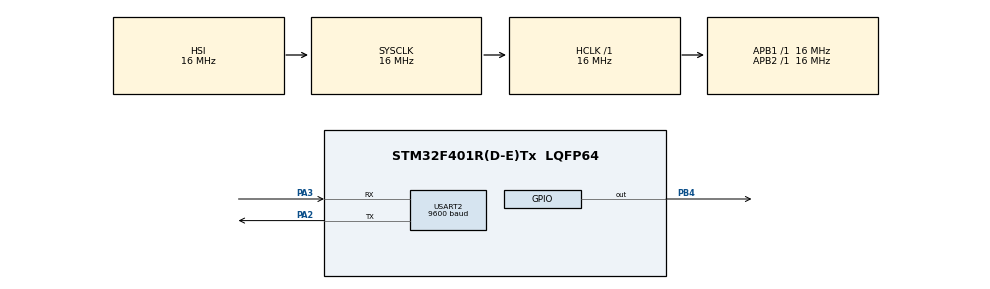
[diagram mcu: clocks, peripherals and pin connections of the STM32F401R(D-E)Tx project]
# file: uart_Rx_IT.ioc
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Mcu.Family=STM32F4
Mcu.Name=STM32F401R(D-E)Tx
Mcu.Package=LQFP64
NVIC.PriorityGroup=NVIC_PRIORITYGROUP_4
NVIC.USART2_IRQn=true\:0\:0\:false\:false\:true\:true
PA2.Mode=Asynchronous
PA2.Signal=USART2_TX
PA3.Mode=Asynchronous
PA3.Signal=USART2_RX
PB4.Signal=GPIO_Output
ProjectManager.HeapSize=0x200
ProjectManager.StackSize=0x400
ProjectManager.TargetToolchain=SW4STM32
RCC.AHBFreq_Value=16000000
RCC.APB1Freq_Value=16000000
RCC.APB1TimFreq_Value=16000000
RCC.APB2Freq_Value=16000000
RCC.APB2TimFreq_Value=16000000
RCC.CortexFreq_Value=16000000
RCC.HCLKFreq_Value=16000000
RCC.HSE_VALUE=25000000
RCC.HSI_VALUE=16000000
RCC.LSE_VALUE=32768
RCC.SYSCLKFreq_VALUE=16000000
RCC.VCOOutputFreq_Value=192000000
USART2.BaudRate=9600
USART2.VirtualMode=VM_ASYNC
board=uart_Rx_IT

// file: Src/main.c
/**
  ******************************************************************************
  * File Name          : main.c
  * Description        : Main program body
  ******************************************************************************
  ** This notice applies to any and all portions of this file
  * that are not between comment pairs USER CODE BEGIN and
  * USER CODE END. Other portions of this file, whether
  * inserted by the user or by software development tools
  * are owned by their respective copyright owners.
  *
  * COPYRIGHT(c) 2018 STMicroelectronics
  *
  * Redistribution and use in source and binary forms, with or without modification,
  * are permitted provided that the following conditions are met:
  *   1. Redistributions of source code must retain the above copyright notice,
  *      this list of conditions and the following disclaimer.
  *   2. Redistributions in binary form must reproduce the above copyright notice,
  *      this list of conditions and the following disclaimer in the documentation
  *      and/or other materials provided with the distribution.
  *   3. Neither the name of STMicroelectronics nor the names of its contributors
  *      may be used to endorse or promote products derived from this software
  *      without specific prior written permission.
  *
  * THIS SOFTWARE IS PROVIDED BY THE COPYRIGHT HOLDERS AND CONTRIBUTORS "AS IS"
  * AND ANY EXPRESS OR IMPLIED WARRANTIES, INCLUDING, BUT NOT LIMITED TO, THE
  * IMPLIED WARRANTIES OF MERCHANTABILITY AND FITNESS FOR A PARTICULAR PURPOSE ARE
  * DISCLAIMED. IN NO EVENT SHALL THE COPYRIGHT HOLDER OR CONTRIBUTORS BE LIABLE
  * FOR ANY DIRECT, INDIRECT, INCIDENTAL, SPECIAL, EXEMPLARY, OR CONSEQUENTIAL
  * DAMAGES (INCLUDING, BUT NOT LIMITED TO, PROCUREMENT OF SUBSTITUTE GOODS OR
  * SERVICES; LOSS OF USE, DATA, OR PROFITS; OR BUSINESS INTERRUPTION) HOWEVER
  * CAUSED AND ON ANY THEORY OF LIABILITY, WHETHER IN CONTRACT, STRICT LIABILITY,
  * OR TORT (INCLUDING NEGLIGENCE OR OTHERWISE) ARISING IN ANY WAY OUT OF THE USE
  * OF THIS SOFTWARE, EVEN IF ADVISED OF THE POSSIBILITY OF SUCH DAMAGE.
  *
  ******************************************************************************
  */

#include "main.h"
#include "stm32f4xx_hal.h"
#include "usart.h"
#include "gpio.h"
#include <string.h>

/* USER CODE BEGIN PV */
/* Private variables ---------------------------------------------------------*/

uint8_t my_buffer[10],UartRcvIndx,UartRxCplt;
char RxBuffer[1024];
uartIpCmdTypeDef cmd;
extern int printf(const char *msg, ...);
int uartCmdParser(char *);
/* USER CODE END PV */

void SystemClock_Config(void);

/* USER CODE BEGIN PFP */
/* Private function prototypes -----------------------------------------------*/
uint8_t uartCmdStore(uint8_t *, char *);
/* USER CODE END PFP */

int main(void)
{

  /* MCU Configuration----------------------------------------------------------*/

  /* Reset of all peripherals, Initializes the Flash interface and the Systick. */
  HAL_Init();

  /* Configure the system clock */
  SystemClock_Config();

  /* Initialize all configured peripherals */
  MX_GPIO_Init();
  MX_USART2_UART_Init();

  /* USER CODE BEGIN 2 */
  /*Configure UART to receive interrupt */

    printf("\nHello, this program demonstrates UART Receive using interrupt using STM32F401RE\n");
    HAL_UART_Receive_IT(&huart2,(uint8_t *)my_buffer,1);
  /* USER CODE END 2 */

  /* Infinite loop */
  /* USER CODE BEGIN WHILE */

  while (1)
  {
	  if(UartRxCplt)
	    {

	  	  //printf("%.*s\n",UartRcvIndx,RxBuffer);
	  	  UartRxCplt = 0;
	  	  //uartCmdParser(RxBuffer);
	  	  memset(RxBuffer,'0',UartRcvIndx);
	  	  UartRcvIndx=0;
	    }
  /* USER CODE END WHILE */

  }

}

/** System Clock Configuration
*/
void SystemClock_Config(void)
{

  RCC_OscInitTypeDef RCC_OscInitStruct;
  RCC_ClkInitTypeDef RCC_ClkInitStruct;

    /**Configure the main internal regulator output voltage
    */
  __HAL_RCC_PWR_CLK_ENABLE();

  __HAL_PWR_VOLTAGESCALING_CONFIG(PWR_REGULATOR_VOLTAGE_SCALE2);

    /**Initializes the CPU, AHB and APB busses clocks
    */
  RCC_OscInitStruct.OscillatorType = RCC_OSCILLATORTYPE_HSI;
  RCC_OscInitStruct.HSIState = RCC_HSI_ON;
  RCC_OscInitStruct.HSICalibrationValue = 16;
  RCC_OscInitStruct.PLL.PLLState = RCC_PLL_NONE;
  if (HAL_RCC_OscConfig(&RCC_OscInitStruct) != HAL_OK)
  {
    _Error_Handler(__FILE__, __LINE__);
  }

    /**Initializes the CPU, AHB and APB busses clocks
    */
  RCC_ClkInitStruct.ClockType = RCC_CLOCKTYPE_HCLK|RCC_CLOCKTYPE_SYSCLK
                              |RCC_CLOCKTYPE_PCLK1|RCC_CLOCKTYPE_PCLK2;
  RCC_ClkInitStruct.SYSCLKSource = RCC_SYSCLKSOURCE_HSI;
  RCC_ClkInitStruct.AHBCLKDivider = RCC_SYSCLK_DIV1;
  RCC_ClkInitStruct.APB1CLKDivider = RCC_HCLK_DIV1;
  RCC_ClkInitStruct.APB2CLKDivider = RCC_HCLK_DIV1;

  if (HAL_RCC_ClockConfig(&RCC_ClkInitStruct, FLASH_LATENCY_0) != HAL_OK)
  {
    _Error_Handler(__FILE__, __LINE__);
  }

    /**Configure the Systick interrupt time
    */
  HAL_SYSTICK_Config(HAL_RCC_GetHCLKFreq()/1000);

    /**Configure the Systick
    */
  HAL_SYSTICK_CLKSourceConfig(SYSTICK_CLKSOURCE_HCLK);

  /* SysTick_IRQn interrupt configuration */
  HAL_NVIC_SetPriority(SysTick_IRQn, 0, 0);
}

/* USER CODE BEGIN 4 */
void HAL_UART_RxCpltCallback(UART_HandleTypeDef *UartHandle)
{

	//printf("\nReceived callback\n");
	/*store UART Rx data to buffer & return the size of received uart data */
	UartRcvIndx = uartCmdStore(my_buffer,RxBuffer);

	//printf("Received char is %c\n",my_buffer[0]);
	/*enable interrupt again after UART reception complete */
	HAL_UART_Receive_IT(UartHandle,(uint8_t *)my_buffer,1);
	//printf("enabled interrupt again\n");

}
uint8_t uartCmdStore(uint8_t *my_buffer,char *RxBuffer)
{
	/* if i/p not '\n': i) uart rx not complete ii) store i/p data to buffer */
	if(*my_buffer!=13)
	{
		if(UartRxCplt==1)
			UartRxCplt = 0;
		RxBuffer[UartRcvIndx++] = my_buffer[0];
	}

	/* if i/p '\n': set uart rx to cplt */
	/*user has to call in main function to analyze the input data stored in Rxbuffer by checking UartRxCplt variable */
	else
	{
		RxBuffer[UartRcvIndx] = '\0';
		UartRxCplt = 1;
		printf("Received data is:");
		printf("%s\n",RxBuffer);
		memset(RxBuffer,'0',UartRcvIndx);
	}
	return UartRcvIndx;

}
/* not used now, but can be used to interpret the input uart command */
int uartCmdParser(char *RxBuffer)
{
	char *uartIp=RxBuffer,*pch,*tmp;
	/* initialize uartIpCmd structure */
	cmd.ctrl = "set";
	cmd.param = "param";
	cmd.value = 0;

	/* get ctrl section of the i/p uart command */
	sprintf(cmd.ctrl,"%.*s",strtok(uartIp,' ')-RxBuffer,RxBuffer);
	tmp = uartIp;
	/* get param section of i/p uart command */
	sprintf(cmd.param,"%.*s",strtok(uartIp,'=')-tmp,tmp);
	/* get value section of i/p uart command */
	int *intUartIp = atoi(uartIp);
	cmd.value = *intUartIp;
	printf("%s,%s,%s\n",cmd.ctrl, cmd.param, cmd.value);
	return 0;
}
/* USER CODE END 4 */

void _Error_Handler(char * file, int line)
{
  while(1)
  {
  }
}

/************************ (C) COPYRIGHT STMicroelectronics *****END OF FILE****/
